# COMPUTE_CLUSTER0_CTL_CFG_PHY register map
Vendor: Texas Instruments
Peripheral module from a debugger description file (folder J7VCL).
Registers are 32-bit, read-write, reset 0x0 unless marked. A register's access mark holds for its fields unless they carry their own. Offsets are as the file gives them; lines under a group give offsets from that group; [hi:lo] are bit positions; {n}, {i} and the like mark numbered series; 'fields as' and 'values as' point back to an identical list; <NAME> marks a mode.

## COMPUTE_CLUSTER0_CTL_CFG_PHY (part 1 of 4)
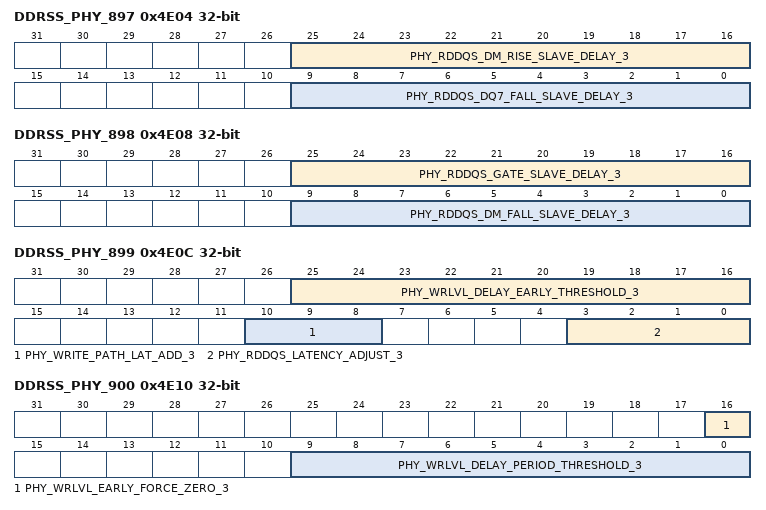
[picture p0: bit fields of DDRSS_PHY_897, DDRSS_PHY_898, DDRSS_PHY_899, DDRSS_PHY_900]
0x4E04 DDRSS_PHY_897
  [25:16] PHY_RDDQS_DM_RISE_SLAVE_DELAY_3 — Rising edge read DQS slave delay setting for DM for slice 3.
  [9:0] PHY_RDDQS_DQ7_FALL_SLAVE_DELAY_3 — Falling edge read DQS slave delay setting for DQ7 for slice 3.
0x4E08 DDRSS_PHY_898
  [25:16] PHY_RDDQS_GATE_SLAVE_DELAY_3 — Read DQS slave delay setting for slice 3.
  [9:0] PHY_RDDQS_DM_FALL_SLAVE_DELAY_3 — Falling edge read DQS slave delay setting for DM for slice 3.
0x4E0C DDRSS_PHY_899
  [25:16] PHY_WRLVL_DELAY_EARLY_THRESHOLD_3 — Write level delay threshold above which will be considered in previous cycle for slice 3.
  [10:8] PHY_WRITE_PATH_LAT_ADD_3 — Number of cycles to delay the incoming dfi_wrdata_en/dfi_wrdata signals for slice 3.
  [3:0] PHY_RDDQS_LATENCY_ADJUST_3 — Number of cycles to delay the incoming dfi_rddata_en for read DQS gate generation for slice 3.
0x4E10 DDRSS_PHY_900
  [16] PHY_WRLVL_EARLY_FORCE_ZERO_3 — Force the final write level delay value (that meets the early threshold) to 0 for slice 3.
  [9:0] PHY_WRLVL_DELAY_PERIOD_THRESHOLD_3 — Write level delay threshold below which will add a cycle of write path latency for slice 3.
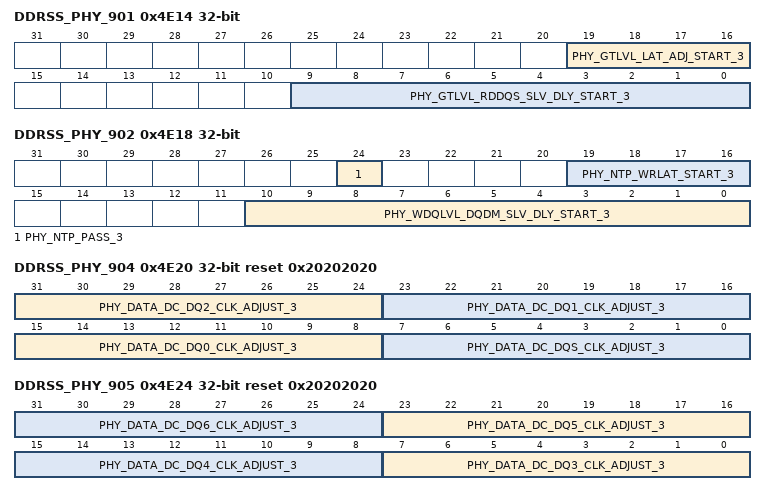
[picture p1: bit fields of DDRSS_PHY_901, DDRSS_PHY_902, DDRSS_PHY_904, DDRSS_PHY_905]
0x4E14 DDRSS_PHY_901
  [19:16] PHY_GTLVL_LAT_ADJ_START_3 — Initial read DQS gate cycle delay from dfi_rddata_en during gate training for slice 3.
  [9:0] PHY_GTLVL_RDDQS_SLV_DLY_START_3 — Initial read DQS gate slave delay setting during gate training for slice 3.
0x4E18 DDRSS_PHY_902
  [24] PHY_NTP_PASS_3 — Indicates if No-topology training found a passing result for slice 3.
  [19:16] PHY_NTP_WRLAT_START_3 — Initial value for phy_write_path_lat_add for No-topology training and early threshold for slice 3.
  [10:0] PHY_WDQLVL_DQDM_SLV_DLY_START_3 — Initial DQ/DM slave delay setting during write data leveling for slice 3.
0x4E1C DDRSS_PHY_903
  [9:0] PHY_RDLVL_RDDQS_DQ_SLV_DLY_START_3 — Read leveling starting value for the DQS/DQ slave delay settings for slice 3.
0x4E20 DDRSS_PHY_904 reset 0x20202020
  [31:24] PHY_DATA_DC_DQ2_CLK_ADJUST_3 — Adjust value of Duty Cycle Adjuster for slice 3.
  [23:16] PHY_DATA_DC_DQ1_CLK_ADJUST_3 — Adjust value of Duty Cycle Adjuster for slice 3.
  [15:8] PHY_DATA_DC_DQ0_CLK_ADJUST_3 — Adjust value of Duty Cycle Adjuster for slice 3.
  [7:0] PHY_DATA_DC_DQS_CLK_ADJUST_3 — Adjust value of Duty Cycle Adjuster for slice 3.
0x4E24 DDRSS_PHY_905 reset 0x20202020
  [8n-17:8n-24] PHY_DATA_DC_DQ{n}_CLK_ADJUST_3 (n=3..6) — Adjust value of Duty Cycle Adjuster for slice 3.
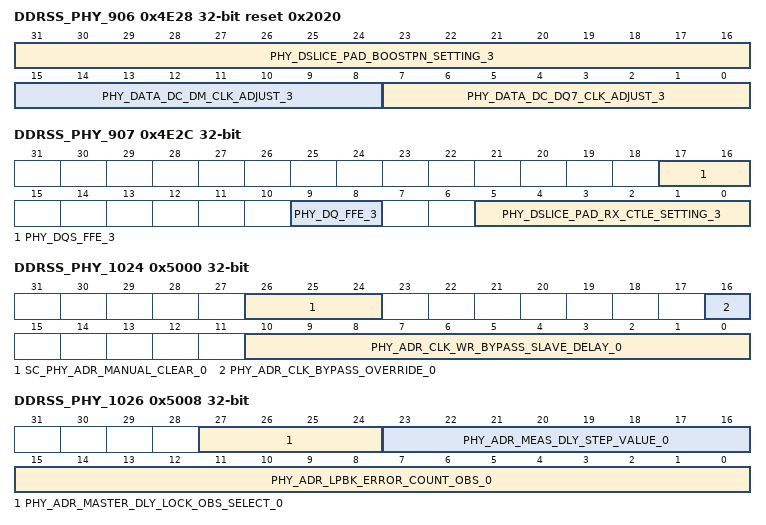
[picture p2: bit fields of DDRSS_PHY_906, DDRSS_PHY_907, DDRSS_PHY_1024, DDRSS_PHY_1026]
0x4E28 DDRSS_PHY_906 reset 0x2020
  [31:16] PHY_DSLICE_PAD_BOOSTPN_SETTING_3 — Setting for boost P/N of pad for slice 3.
  [15:8] PHY_DATA_DC_DM_CLK_ADJUST_3 — Adjust value of Duty Cycle Adjuster for slice 3.
  [7:0] PHY_DATA_DC_DQ7_CLK_ADJUST_3 — Adjust value of Duty Cycle Adjuster for slice 3.
0x4E2C DDRSS_PHY_907
  [17:16] PHY_DQS_FFE_3 — TX_FFE setting for DQS pad for slice 3.
  [9:8] PHY_DQ_FFE_3 — TX_FFE setting for DQ/DM pad for slice 3.
  [5:0] PHY_DSLICE_PAD_RX_CTLE_SETTING_3 — Setting for RX ctle P/N of pad for slice 3.
0x5000 DDRSS_PHY_1024 access per field
  [26:24] SC_PHY_ADR_MANUAL_CLEAR_0 wo — Manual reset/clear of internal logic for address slice 0.
  [16] PHY_ADR_CLK_BYPASS_OVERRIDE_0 rw — Bypass mode override setting for address slice 0.
  [10:0] PHY_ADR_CLK_WR_BYPASS_SLAVE_DELAY_0 rw — Command/Address clock bypass mode slave delay setting for address slice 0.
0x5004 DDRSS_PHY_1025 ro reset 0x1000
  [31:0] PHY_ADR_LPBK_RESULT_OBS_0 — Observation register containing loopback status/results for address slice 0.
0x5008 DDRSS_PHY_1026 access per field
  [27:24] PHY_ADR_MASTER_DLY_LOCK_OBS_SELECT_0 rw — Select value to map the internal master delay observation registers to the accessible master delay observation register for address slice 0.
  [23:16] PHY_ADR_MEAS_DLY_STEP_VALUE_0 ro — Contains the fraction of a cycle in 1 delay element numerator with demominator of 512, for address slice 0.
  [15:0] PHY_ADR_LPBK_ERROR_COUNT_OBS_0 ro — Observation register containing total number of loopback error data for address slice 0.
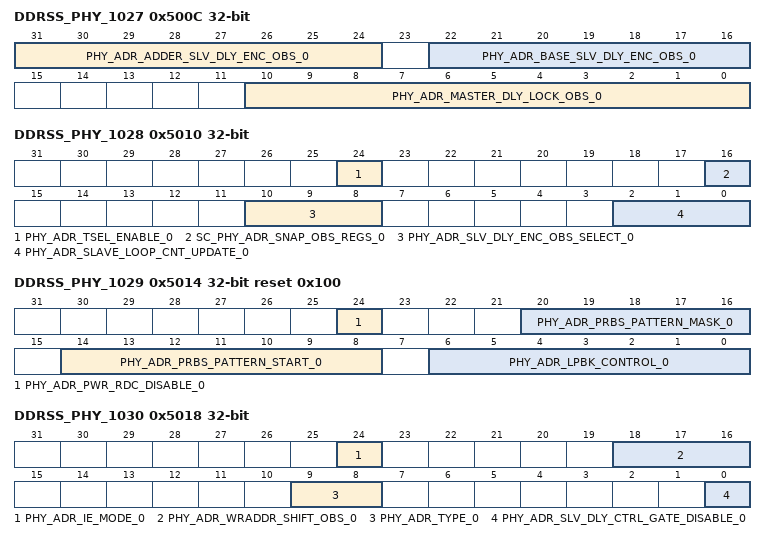
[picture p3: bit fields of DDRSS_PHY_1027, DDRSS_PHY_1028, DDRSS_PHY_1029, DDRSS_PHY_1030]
0x500C DDRSS_PHY_1027 ro
  [31:24] PHY_ADR_ADDER_SLV_DLY_ENC_OBS_0 — Observation register containing addr slave delay for address slice 0.
  [22:16] PHY_ADR_BASE_SLV_DLY_ENC_OBS_0 — Observation register containing base slave delay for address slice 0.
  [10:0] PHY_ADR_MASTER_DLY_LOCK_OBS_0 — Observation register containing master delay results for address slice 0.
0x5010 DDRSS_PHY_1028 access per field
  [24] PHY_ADR_TSEL_ENABLE_0 rw — Enables tsel_en for address slice 0.
  [16] SC_PHY_ADR_SNAP_OBS_REGS_0 wo — Initiates a snapshot of the internal observation registers for address slice 0.
  [10:8] PHY_ADR_SLV_DLY_ENC_OBS_SELECT_0 rw — Select value to map the addr bits delay observation registers to the accessible delay observation register for address slice 0.
  [2:0] PHY_ADR_SLAVE_LOOP_CNT_UPDATE_0 rw — Reserved for address slice 0.
0x5014 DDRSS_PHY_1029 reset 0x100
  [24] PHY_ADR_PWR_RDC_DISABLE_0 — Power reduction disable for address slice 0.
  [20:16] PHY_ADR_PRBS_PATTERN_MASK_0 — PRBS7 mask signal for address slice 0.
  [14:8] PHY_ADR_PRBS_PATTERN_START_0 — PRBS7 start pattern for address slice 0.
  [6:0] PHY_ADR_LPBK_CONTROL_0 — Loopback control bits for address slice 0.
0x5018 DDRSS_PHY_1030 access per field
  [24] PHY_ADR_IE_MODE_0 rw — Input enable control for address slice 0.
  [18:16] PHY_ADR_WRADDR_SHIFT_OBS_0 ro — Observation register containing automatic half cycle and cycle shift values for address slice 0.
  [9:8] PHY_ADR_TYPE_0 rw — DRAM type for address slice 0.
  [0] PHY_ADR_SLV_DLY_CTRL_GATE_DISABLE_0 rw — Power reduction slv_dly_control block gate disable for address slice 0.
0x501C DDRSS_PHY_1031
  [26:0] PHY_ADR_DDL_MODE_0 — DDL mode for address slice 0.
0x5020 DDRSS_PHY_1032
  [5:0] PHY_ADR_DDL_MASK_0 — DDL mask for address slice 0.
0x5024 DDRSS_PHY_1033 ro
  [31:0] PHY_ADR_DDL_TEST_OBS_0 — Observation register containing DDL test bits for address slice 0.
0x5028 DDRSS_PHY_1034 ro
  [31:0] PHY_ADR_DDL_TEST_MSTR_DLY_OBS_0 — Observation register containing master DDL bits for address slice 0.
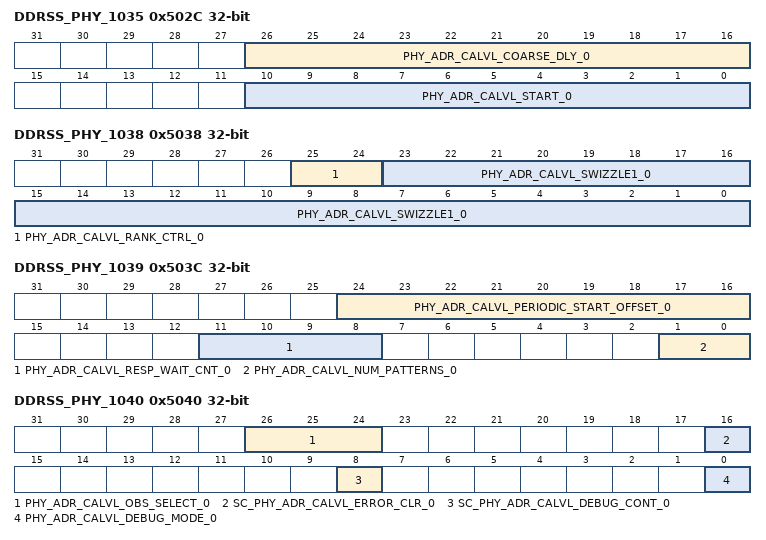
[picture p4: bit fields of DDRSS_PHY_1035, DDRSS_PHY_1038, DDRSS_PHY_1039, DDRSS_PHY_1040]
0x502C DDRSS_PHY_1035
  [26:16] PHY_ADR_CALVL_COARSE_DLY_0 — Coarse CA training DDL increment value for address slice 0.
  [10:0] PHY_ADR_CALVL_START_0 — CA training DDL start value for address slice 0.
0x5030 DDRSS_PHY_1036
  [10:0] PHY_ADR_CALVL_QTR_0 — CA training DDL quarter cycle delay value for address slice 0.
0x5034 DDRSS_PHY_1037
  [23:0] PHY_ADR_CALVL_SWIZZLE0_0 — CA training RD DQ bit swizzle map 0 for address slice 0.
0x5038 DDRSS_PHY_1038
  [25:24] PHY_ADR_CALVL_RANK_CTRL_0 — CA training rank aggregation control bits for address slice 0.
  [23:0] PHY_ADR_CALVL_SWIZZLE1_0 — CA training RD DQ bit swizzle map 1 for address slice 0.
0x503C DDRSS_PHY_1039
  [24:16] PHY_ADR_CALVL_PERIODIC_START_OFFSET_0 — Relative offset to start periodic CALVL from previous result
  [11:8] PHY_ADR_CALVL_RESP_WAIT_CNT_0 — Number of samples to wait before sampling response during CA training for address slice 0.
  [1:0] PHY_ADR_CALVL_NUM_PATTERNS_0 — Number of patterns to use during CA training for address slice 0.
0x5040 DDRSS_PHY_1040 access per field
  [26:24] PHY_ADR_CALVL_OBS_SELECT_0 rw — CA bit lane to observe result from OBS0 during CA training for address slice 0.
  [16] SC_PHY_ADR_CALVL_ERROR_CLR_0 wo — Clears the CA training state machine error status for address slice 0.
  [8] SC_PHY_ADR_CALVL_DEBUG_CONT_0 wo — Allows the CA training state machine to advance (when in debug mode) for address slice 0.
  [0] PHY_ADR_CALVL_DEBUG_MODE_0 rw — Enables CA training debug mode for address slice 0.
0x5044 DDRSS_PHY_1041 ro
  [31:0] PHY_ADR_CALVL_CH0_OBS0_0 — Observation register for CA training for channel 0 slice 0.
0x5048 DDRSS_PHY_1042 ro
  [31:0] PHY_ADR_CALVL_CH1_OBS0_0 — Observation register for CA training for channel 1 slice 0.
0x504C DDRSS_PHY_1043 ro
  [31:0] PHY_ADR_CALVL_OBS1_0 — Observation register contains general CA training bits for slice 0.
0x5050 DDRSS_PHY_1044 ro
  [31:0] PHY_ADR_CALVL_OBS2_0 — Observation register contains periodic CA training bits for slice 0.
0x5054 DDRSS_PHY_1045
  [19:0] PHY_ADR_CALVL_FG_0_0 — CA training foreground pattern 0 for address slice 0.
0x5058 DDRSS_PHY_1046
  [19:0] PHY_ADR_CALVL_BG_0_0 — CA training background pattern 0 for address slice 0.
0x505C DDRSS_PHY_1047
  [19:0] PHY_ADR_CALVL_FG_1_0 — CA training foreground pattern 1 for address slice 0.
0x5060 DDRSS_PHY_1048
  [19:0] PHY_ADR_CALVL_BG_1_0 — CA training background pattern 1 for address slice 0.
0x5064 DDRSS_PHY_1049
  [19:0] PHY_ADR_CALVL_FG_2_0 — CA training foreground pattern 2 for address slice 0.
0x5068 DDRSS_PHY_1050
  [19:0] PHY_ADR_CALVL_BG_2_0 — CA training background pattern 2 for address slice 0.
0x506C DDRSS_PHY_1051
  [19:0] PHY_ADR_CALVL_FG_3_0 — CA training foreground pattern 3 for address slice 0.
0x5070 DDRSS_PHY_1052
  [19:0] PHY_ADR_CALVL_BG_3_0 — CA training background pattern 3 for address slice 0.
0x5074 DDRSS_PHY_1053
  [23:0] PHY_ADR_ADDR_SEL_0 — Selects which DFI address pins connect to which CA pins for LPDDR3/4 for address slice 0.
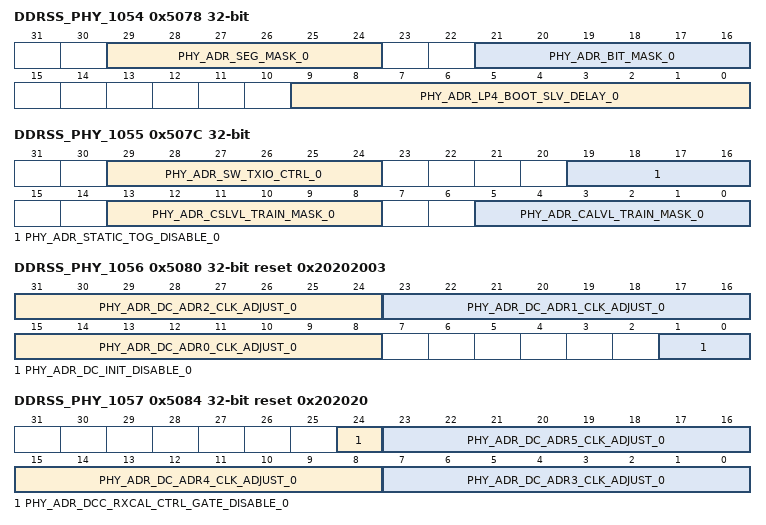
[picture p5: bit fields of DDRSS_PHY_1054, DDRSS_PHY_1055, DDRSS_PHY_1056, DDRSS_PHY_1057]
0x5078 DDRSS_PHY_1054
  [29:24] PHY_ADR_SEG_MASK_0 — Segment mask bit for address slice 0.
  [21:16] PHY_ADR_BIT_MASK_0 — Mask bit for address slice 0.
  [9:0] PHY_ADR_LP4_BOOT_SLV_DELAY_0 — Address slave delay setting during the LPDDR4 boot frequency operation for address slice 0.
0x507C DDRSS_PHY_1055
  [29:24] PHY_ADR_SW_TXIO_CTRL_0 — Controls address pad output enable for address slice 0.
  [19:16] PHY_ADR_STATIC_TOG_DISABLE_0 — Toggle control during static activity for address slice 0.
  [13:8] PHY_ADR_CSLVL_TRAIN_MASK_0 — Mask bit for CS training participation for address slice 0.
  [5:0] PHY_ADR_CALVL_TRAIN_MASK_0 — Mask bit for CA training participation for address slice 0.
0x5080 DDRSS_PHY_1056 reset 0x20202003
  [31:24] PHY_ADR_DC_ADR2_CLK_ADJUST_0 — Adjust value of Clock Duty Cycle Adjuster lane 2 for address slice 0.
  [23:16] PHY_ADR_DC_ADR1_CLK_ADJUST_0 — Adjust value of Clock Duty Cycle Adjuster lane 1 for address slice 0.
  [15:8] PHY_ADR_DC_ADR0_CLK_ADJUST_0 — Adjust value of Clock Duty Cycle Adjuster lane 0 for address slice 0.
  [1:0] PHY_ADR_DC_INIT_DISABLE_0 — Duty Cycle Corrector disable at initialization for address slice 0.
0x5084 DDRSS_PHY_1057 reset 0x202020
  [24] PHY_ADR_DCC_RXCAL_CTRL_GATE_DISABLE_0 — DCC and RX_CAL clk gate disable for address slice 0.
  [23:16] PHY_ADR_DC_ADR5_CLK_ADJUST_0 — Adjust value of Clock Duty Cycle Adjuster lane 5 for address slice 0.
  [15:8] PHY_ADR_DC_ADR4_CLK_ADJUST_0 — Adjust value of Clock Duty Cycle Adjuster lane 4 for address slice 0.
  [7:0] PHY_ADR_DC_ADR3_CLK_ADJUST_0 — Adjust value of Clock Duty Cycle Adjuster lane 3 for address slice 0.
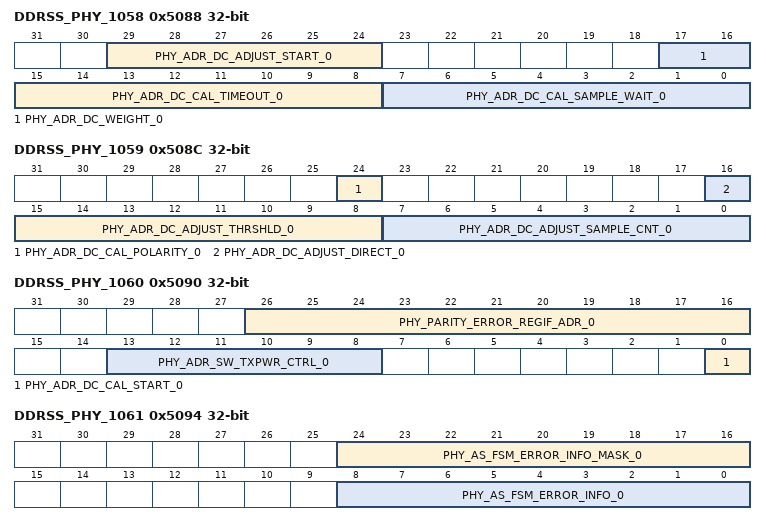
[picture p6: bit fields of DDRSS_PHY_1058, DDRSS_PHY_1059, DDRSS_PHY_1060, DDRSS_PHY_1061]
0x5088 DDRSS_PHY_1058
  [29:24] PHY_ADR_DC_ADJUST_START_0 — DCC calibration starting value for address slice 0.
  [17:16] PHY_ADR_DC_WEIGHT_0 — DCC weighting factor base value for address slice 0.
  [15:8] PHY_ADR_DC_CAL_TIMEOUT_0 — DCC number of iterations to wait before timeout for address slice 0.
  [7:0] PHY_ADR_DC_CAL_SAMPLE_WAIT_0 — DCC cycles to wait after calibration change before sampling results for address slice 0.
0x508C DDRSS_PHY_1059
  [24] PHY_ADR_DC_CAL_POLARITY_0 — DCC calibration polarity for address slice 0.
  [16] PHY_ADR_DC_ADJUST_DIRECT_0 — DCC adjust direction for address slice 0.
  [15:8] PHY_ADR_DC_ADJUST_THRSHLD_0 — DCC adjust threshold around the mid-point for address slice 0.
  [7:0] PHY_ADR_DC_ADJUST_SAMPLE_CNT_0 — DCC number of samples to take for address slice 0.
0x5090 DDRSS_PHY_1060
  [26:16] PHY_PARITY_ERROR_REGIF_ADR_0 — Inject parity error to register interface signals for address slice 0.
  [13:8] PHY_ADR_SW_TXPWR_CTRL_0 — Disable address output enables in deep sleep mode for address slice 0.
  [0] PHY_ADR_DC_CAL_START_0 — DCC Manual trigger for address slice 0.
0x5094 DDRSS_PHY_1061 access per field
  [24:16] PHY_AS_FSM_ERROR_INFO_MASK_0 rw — FSM Error Info Mask for address slice 0.
  [8:0] PHY_AS_FSM_ERROR_INFO_0 ro — FSM Error Info for address slice 0.
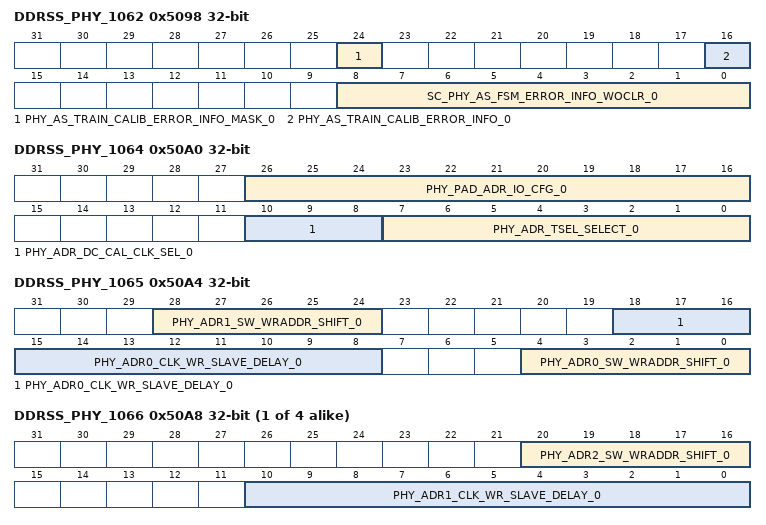
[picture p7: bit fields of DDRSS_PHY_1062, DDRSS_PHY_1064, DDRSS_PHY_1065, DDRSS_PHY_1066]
0x5098 DDRSS_PHY_1062 access per field
  [24] PHY_AS_TRAIN_CALIB_ERROR_INFO_MASK_0 rw — Training/Calibration Error Info Mask for address slice 0.
  [16] PHY_AS_TRAIN_CALIB_ERROR_INFO_0 ro — Training/Calibration Error Info for address slice 0.
  [8:0] SC_PHY_AS_FSM_ERROR_INFO_WOCLR_0 wo — FSM Error Info clear for address slice 0.
0x509C DDRSS_PHY_1063 wo
  [0] SC_PHY_AS_TRAIN_CALIB_ERROR_INFO_WOCLR_0 — Training/Calibration Error Info clear for address slice 0.
0x50A0 DDRSS_PHY_1064
  [26:16] PHY_PAD_ADR_IO_CFG_0 — Controls I/O pads for address pad for address slice 0.
  [10:8] PHY_ADR_DC_CAL_CLK_SEL_0 — DCC CAL clock for address slice 0.
  [7:0] PHY_ADR_TSEL_SELECT_0 — Tsel select values for address slice 0.
0x50A4 DDRSS_PHY_1065
  [28:24] PHY_ADR1_SW_WRADDR_SHIFT_0 — Manual override of CA bit 1 of automatic half_cycle_shift/cycle_shift for address slice 0.
  [18:8] PHY_ADR0_CLK_WR_SLAVE_DELAY_0 — CA bit 0 slave delay setting for address slice 0.
  [4:0] PHY_ADR0_SW_WRADDR_SHIFT_0 — Manual override of CA bit 0 of automatic half_cycle_shift/cycle_shift for address slice 0.
{0x4000+4i} DDRSS_PHY_{i} (i=1066..1069)
  [20:16] PHY_ADR{i-1064}_SW_WRADDR_SHIFT_0 — Manual override of CA bit {i-1064} of automatic half_cycle_shift/cycle_shift for address slice 0.
  [10:0] PHY_ADR{i-1065}_CLK_WR_SLAVE_DELAY_0 — CA bit {i-1065} slave delay setting for address slice 0.
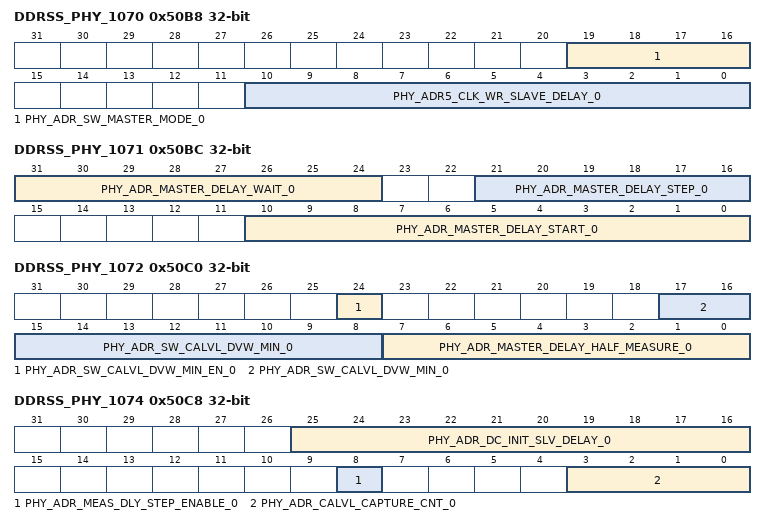
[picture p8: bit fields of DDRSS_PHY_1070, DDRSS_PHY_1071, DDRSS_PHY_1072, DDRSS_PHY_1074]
0x50B8 DDRSS_PHY_1070
  [19:16] PHY_ADR_SW_MASTER_MODE_0 — Master delay line override settings for address slice 0.
  [10:0] PHY_ADR5_CLK_WR_SLAVE_DELAY_0 — CA bit 5 slave delay setting for address slice 0.
0x50BC DDRSS_PHY_1071
  [31:24] PHY_ADR_MASTER_DELAY_WAIT_0 — Wait cycles for master delay line locking algorithm for address slice 0.
  [21:16] PHY_ADR_MASTER_DELAY_STEP_0 — Incremental step size for master delay line locking algorithm for address slice 0.
  [10:0] PHY_ADR_MASTER_DELAY_START_0 — Start value for master delay line locking algorithm for address slice 0.
0x50C0 DDRSS_PHY_1072
  [24] PHY_ADR_SW_CALVL_DVW_MIN_EN_0 — Enables the software override data valid window size during CA training for address slice 0.
  [17:8] PHY_ADR_SW_CALVL_DVW_MIN_0 — Sets the software override data valid window size during CA training for address slice 0.
  [7:0] PHY_ADR_MASTER_DELAY_HALF_MEASURE_0 — Defines the number of delay line elements to be considered in determing whether to lock to a half clock cycle for the master in address slice 0
0x50C4 DDRSS_PHY_1073
  [3:0] PHY_ADR_CALVL_DLY_STEP_0 — Sets the delay step size plus 1 during CA training for address slice 0.
0x50C8 DDRSS_PHY_1074
  [25:16] PHY_ADR_DC_INIT_SLV_DELAY_0 — DCC initialization value of write ADDR slave delay for address slice 0.
  [8] PHY_ADR_MEAS_DLY_STEP_ENABLE_0 — Enables delay parameter setting using phy_adr_meas_dly_step_value for address slice 0.
  [3:0] PHY_ADR_CALVL_CAPTURE_CNT_0 — Number of samples to take at each ADDR slave delay setting during CA training for address slice 0.
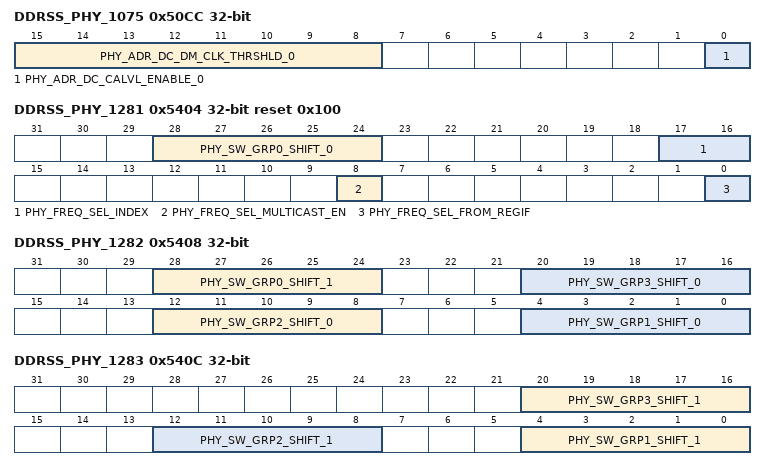
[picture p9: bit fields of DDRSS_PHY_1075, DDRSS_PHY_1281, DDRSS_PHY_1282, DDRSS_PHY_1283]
0x50CC DDRSS_PHY_1075
  [15:8] PHY_ADR_DC_DM_CLK_THRSHLD_0 — DCC clock measurement cell threshold offset for address slice 0.
  [0] PHY_ADR_DC_CALVL_ENABLE_0 — DCC enable duty cycle adjust during CA leveling for address slice 0.
0x5400 DDRSS_PHY_1280
  [1:0] PHY_FREQ_SEL — Specifies which copy of the frequency-dependent timing parameters will be used by the PHY.
0x5404 DDRSS_PHY_1281 reset 0x100
  [28:24] PHY_SW_GRP0_SHIFT_0 — Address slice slave delay setting for address slice 4.
  [17:16] PHY_FREQ_SEL_INDEX — Selects which frequency set to update when PHY_FREQ_SEL_MULTICAST_EN is not set.
  [8] PHY_FREQ_SEL_MULTICAST_EN — When set, a register write will update parameters for all frequency sets simultaneously.
  [0] PHY_FREQ_SEL_FROM_REGIF — Indicates which source is used to select the frequency copy.
0x5408 DDRSS_PHY_1282
  [28:24] PHY_SW_GRP0_SHIFT_1 — Address slice slave delay setting for address slice 4.
  [20:16] PHY_SW_GRP3_SHIFT_0 — Address slice slave delay setting for address slice 4.
  [12:8] PHY_SW_GRP2_SHIFT_0 — Address slice slave delay setting for address slice 4.
  [4:0] PHY_SW_GRP1_SHIFT_0 — Address slice slave delay setting for address slice 4.
0x540C DDRSS_PHY_1283
  [20:16] PHY_SW_GRP3_SHIFT_1 — Address slice slave delay setting for address slice 4.
  [12:8] PHY_SW_GRP2_SHIFT_1 — Address slice slave delay setting for address slice 4.
  [4:0] PHY_SW_GRP1_SHIFT_1 — Address slice slave delay setting for address slice 4.
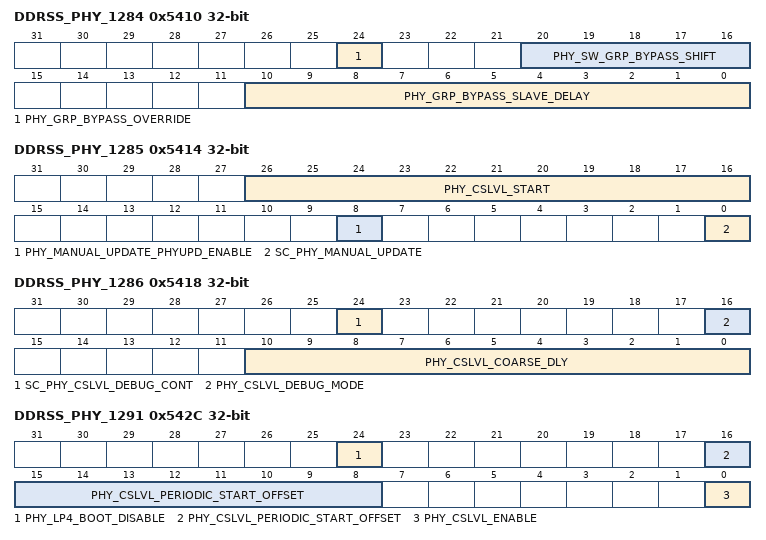
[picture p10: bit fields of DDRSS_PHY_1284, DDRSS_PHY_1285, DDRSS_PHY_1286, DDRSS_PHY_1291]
0x5410 DDRSS_PHY_1284
  [24] PHY_GRP_BYPASS_OVERRIDE — Address/control group slice bypass mode override setting.
  [20:16] PHY_SW_GRP_BYPASS_SHIFT — Address/control group slice bypass mode shift settings.
  [10:0] PHY_GRP_BYPASS_SLAVE_DELAY — Address/control group slice bypass mode slave delay setting.
0x5414 DDRSS_PHY_1285 access per field
  [26:16] PHY_CSLVL_START rw — Defines the CS training DDL start value.
  [8] PHY_MANUAL_UPDATE_PHYUPD_ENABLE rw — Manual update selection of all slave delay line settings.
  [0] SC_PHY_MANUAL_UPDATE wo — Manual update of all slave delay line settings.
0x5418 DDRSS_PHY_1286 access per field
  [24] SC_PHY_CSLVL_DEBUG_CONT wo — Allows the CS training state machine to advance (when in debug mode).
  [16] PHY_CSLVL_DEBUG_MODE rw — Enables CS training debug mode.
  [10:0] PHY_CSLVL_COARSE_DLY rw — Defines the CS training DDL coarse cycle delay value.
0x541C DDRSS_PHY_1287 wo
  [0] SC_PHY_CSLVL_ERROR_CLR — Clears the CS training state machine error status.
0x5420 DDRSS_PHY_1288 ro reset 0x6800000
  [31:0] PHY_CSLVL_OBS0 — Observation register for CS training delay values.
0x5424 DDRSS_PHY_1289 ro
  [31:0] PHY_CSLVL_OBS1 — Observation register for CS training algorithm status.
0x5428 DDRSS_PHY_1290 ro
  [31:0] PHY_CSLVL_OBS2 — Observation register for periodic CS training delay values.
0x542C DDRSS_PHY_1291
  [24] PHY_LP4_BOOT_DISABLE — Controls the handling of the DFI frequency.
  [16:8] PHY_CSLVL_PERIODIC_START_OFFSET — Defines the relative offset from previous LE and TE to start periodic CSLVL with.
  [0] PHY_CSLVL_ENABLE — CS training enable.
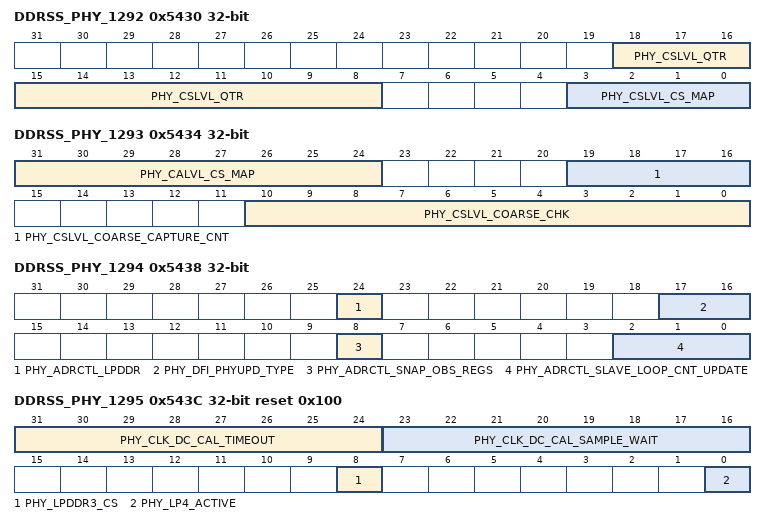
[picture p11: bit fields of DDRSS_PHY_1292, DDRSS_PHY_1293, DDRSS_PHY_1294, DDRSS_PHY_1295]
0x5430 DDRSS_PHY_1292
  [18:8] PHY_CSLVL_QTR — Defines the CS training DDL 1/4 cycle delay value.
  [3:0] PHY_CSLVL_CS_MAP — CS training map.
0x5434 DDRSS_PHY_1293
  [31:24] PHY_CALVL_CS_MAP — Defines the slice numbers associated with each CS during CA training.
  [19:16] PHY_CSLVL_COARSE_CAPTURE_CNT — Defines the number of samples to take at each GRP slave delay setting during CS training coarse CA training.
  [10:0] PHY_CSLVL_COARSE_CHK — Defines the CS training coarse CA training DDL 1/16th cycle delay value.
0x5438 DDRSS_PHY_1294 access per field
  [24] PHY_ADRCTL_LPDDR rw — Adds a cycle of delay for the address/control slices to match the address slice.
  [17:16] PHY_DFI_PHYUPD_TYPE rw — Defines the value of the dfi_phyupd_type output signal to MC.
  [8] PHY_ADRCTL_SNAP_OBS_REGS wo — Initiates a snapshot of the internal observation registers for the address/control block.
  [2:0] PHY_ADRCTL_SLAVE_LOOP_CNT_UPDATE rw — Reserved for the address/control master.
0x543C DDRSS_PHY_1295 reset 0x100
  [31:24] PHY_CLK_DC_CAL_TIMEOUT — Duty cycle correction maximum iteration count.
  [23:16] PHY_CLK_DC_CAL_SAMPLE_WAIT — Number of cal clock cycles to wait for a sample to be taken.
  [8] PHY_LPDDR3_CS — Alters reset state polarity for LPDDR chip selects.
  [0] PHY_LP4_ACTIVE — Indicates an LPDDR4 device is connected to the PHY.
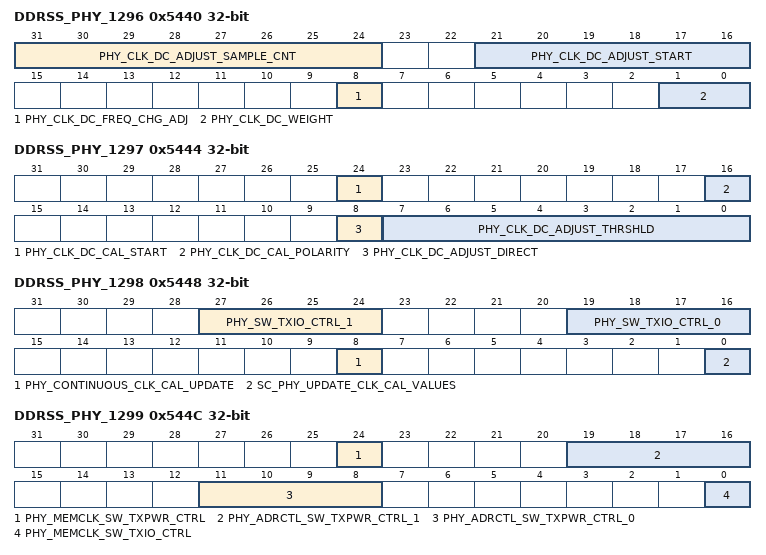
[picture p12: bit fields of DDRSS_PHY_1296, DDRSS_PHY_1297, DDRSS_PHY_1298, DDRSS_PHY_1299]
0x5440 DDRSS_PHY_1296
  [31:24] PHY_CLK_DC_ADJUST_SAMPLE_CNT — Duty cycle correction algorithm sample count per adjustment setting.
  [21:16] PHY_CLK_DC_ADJUST_START — Duty cycle correction algorithm adjustment starting value.
  [8] PHY_CLK_DC_FREQ_CHG_ADJ — Duty cycle correction during frequency change control.
  [1:0] PHY_CLK_DC_WEIGHT — Duty cycle correction weighting factor base value.
0x5444 DDRSS_PHY_1297
  [24] PHY_CLK_DC_CAL_START — Duty cycle correction calibration manual start.
  [16] PHY_CLK_DC_CAL_POLARITY — Duty cycle correction algorithm measurement polarity.
  [8] PHY_CLK_DC_ADJUST_DIRECT — Duty cycle correction algorithm adjustment direction.
  [7:0] PHY_CLK_DC_ADJUST_THRSHLD — Duty cycle correction algorithm threshold delta comparison.
0x5448 DDRSS_PHY_1298 access per field
  [27:24] PHY_SW_TXIO_CTRL_1 rw — This register is used to control if command pad (CS/RAS...) should be shutoff for TX mode.
  [19:16] PHY_SW_TXIO_CTRL_0 rw — This register is used to control if command pad (CS/RAS...) should be shutoff for TX mode.
  [8] PHY_CONTINUOUS_CLK_CAL_UPDATE rw — Continuous update of all latest PVTP,PVTN and PVTR values to the CLK IO pads.
  [0] SC_PHY_UPDATE_CLK_CAL_VALUES wo — Manual update of all latest PVTP,PVTN and PVTR values to the CLK IO pads.
0x544C DDRSS_PHY_1299
  [24] PHY_MEMCLK_SW_TXPWR_CTRL — This register is used to control if clk pads should be shutoff for TX mode in deep sleep mode.
  [19:16] PHY_ADRCTL_SW_TXPWR_CTRL_1 — This register is used to control if address/command pad (address/CS/RAS...) should be shutoff for TX mode in deep sleep mode.
  [11:8] PHY_ADRCTL_SW_TXPWR_CTRL_0 — This register is used to control if address/command pad (address/CS/RAS...) should be shutoff for TX mode in deep sleep mode.
  [0] PHY_MEMCLK_SW_TXIO_CTRL — This register is used to control if clk pads should be shutoff for TX mode.
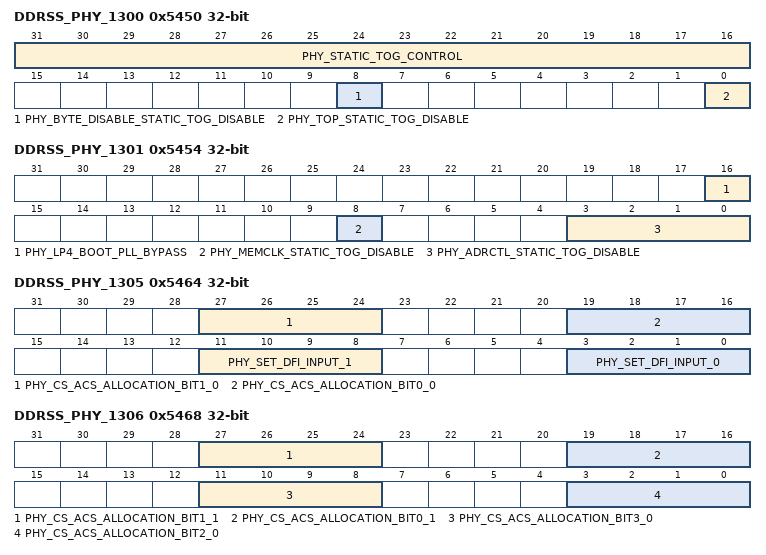
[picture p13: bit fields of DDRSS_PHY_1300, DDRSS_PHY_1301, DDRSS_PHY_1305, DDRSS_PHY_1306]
0x5450 DDRSS_PHY_1300
  [31:16] PHY_STATIC_TOG_CONTROL — Clock divider to create toggle signal.
  [8] PHY_BYTE_DISABLE_STATIC_TOG_DISABLE — Control to disable the toggle signal for data slice during static activity when dfi_data_byte_disable is asserted.
  [0] PHY_TOP_STATIC_TOG_DISABLE — Disables the generation of the toggle for static clock based paths in the PHY to prevent assymetric aging.
0x5454 DDRSS_PHY_1301
  [16] PHY_LP4_BOOT_PLL_BYPASS — PHY clock PLL bypass select.
  [8] PHY_MEMCLK_STATIC_TOG_DISABLE — Control to disable toggle during static activity.
  [3:0] PHY_ADRCTL_STATIC_TOG_DISABLE — Control to disable toggle during static activity.
0x5458 DDRSS_PHY_1302 ro reset 0x10082650
  [31:0] PHY_CLK_SWITCH_OBS — Observation register for Clock switch state machine READ-ONLY
0x545C DDRSS_PHY_1303
  [15:0] PHY_PLL_WAIT — PHY clock PLL wait time after locking.
0x5460 DDRSS_PHY_1304
  [0] PHY_SW_PLL_BYPASS — PHY clock PLL bypass select.
0x5464 DDRSS_PHY_1305
  [27:24] PHY_CS_ACS_ALLOCATION_BIT1_0 — The map for which chip select is associated with each bit in the adrctl slice 0.
  [19:16] PHY_CS_ACS_ALLOCATION_BIT0_0 — The map for which chip select is associated with each bit in the adrctl slice 0.
  [11:8] PHY_SET_DFI_INPUT_1 — Used to indicate the default value of the adrctl slice bits.
  [3:0] PHY_SET_DFI_INPUT_0 — Used to indicate the default value of the adrctl slice bits.
0x5468 DDRSS_PHY_1306
  [27:24] PHY_CS_ACS_ALLOCATION_BIT1_1 — The map for which chip select is associated with each bit in the adrctl slice 1.
  [19:16] PHY_CS_ACS_ALLOCATION_BIT0_1 — The map for which chip select is associated with each bit in the adrctl slice 1.
  [11:8] PHY_CS_ACS_ALLOCATION_BIT3_0 — The map for which chip select is associated with each bit in the adrctl slice 0.
  [3:0] PHY_CS_ACS_ALLOCATION_BIT2_0 — The map for which chip select is associated with each bit in the adrctl slice 0.
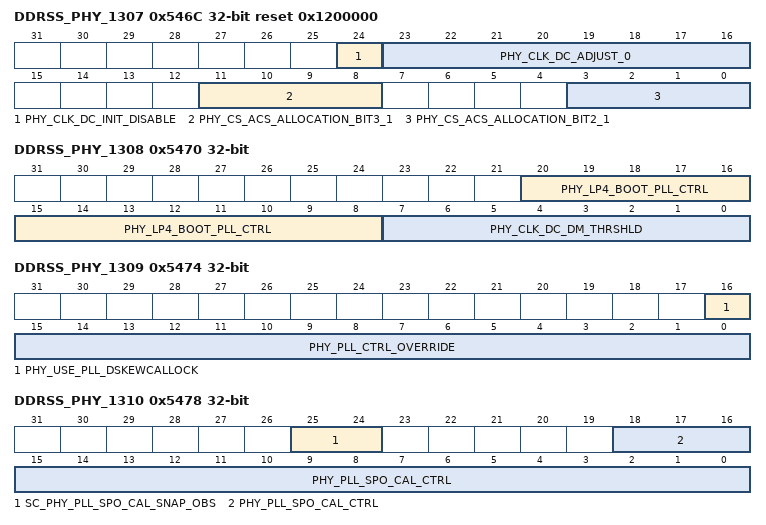
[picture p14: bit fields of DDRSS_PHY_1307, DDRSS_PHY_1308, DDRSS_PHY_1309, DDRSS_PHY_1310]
0x546C DDRSS_PHY_1307 reset 0x1200000
  [24] PHY_CLK_DC_INIT_DISABLE — Disable duty cycle adjust at initialization.
  [23:16] PHY_CLK_DC_ADJUST_0 — Adjust value of Duty Cycle Adjuster for clock slice 0.
  [11:8] PHY_CS_ACS_ALLOCATION_BIT3_1 — The map for which chip select is associated with each bit in the adrctl slice 1.
  [3:0] PHY_CS_ACS_ALLOCATION_BIT2_1 — The map for which chip select is associated with each bit in the adrctl slice 1.
0x5470 DDRSS_PHY_1308
  [20:8] PHY_LP4_BOOT_PLL_CTRL — PHY deskew PLL controls for LPDDR4 boot frequency.
  [7:0] PHY_CLK_DC_DM_THRSHLD — Data measurement cell threshold offset.
0x5474 DDRSS_PHY_1309
  [16] PHY_USE_PLL_DSKEWCALLOCK — Use DSKEWCALLOCK or not.
  [15:0] PHY_PLL_CTRL_OVERRIDE — Individual PHY clock PLL control overrides.
0x5478 DDRSS_PHY_1310 access per field
  [25:24] SC_PHY_PLL_SPO_CAL_SNAP_OBS wo — Register command to take a snapshot of PLL output.
  [18:0] PHY_PLL_SPO_CAL_CTRL rw — PLL SPO Cal controls.
0x547C DDRSS_PHY_1311 access per field
  [17:16] SC_PHY_PLL_CAL_CLK_MEAS wo — Register command to initiate cal_clklout clock frequency measurement.
  [9:0] PHY_PLL_CAL_CLK_MEAS_CYCLES rw — Measurement cycles of cal_clkout clock.
0x5480 DDRSS_PHY_1312 ro
  [15:0] PHY_PLL_OBS_0 — PHY TOP level clock PLL_0 observe values.
0x5484 DDRSS_PHY_1313 ro
  [16:0] PHY_PLL_SPO_CAL_OBS_0 — PHY TOP level PLL_0 SPO Cal observe values.
0x5488 DDRSS_PHY_1314 ro
  [17:0] PHY_PLL_CAL_CLK_MEAS_OBS_0 — PHY TOP level PLL_0 cal_clkout measurement observe values.
0x548C DDRSS_PHY_1315 ro
  [15:0] PHY_PLL_OBS_1 — PHY TOP level clock PLL_1 observe values.
0x5490 DDRSS_PHY_1316 ro
  [16:0] PHY_PLL_SPO_CAL_OBS_1 — PHY TOP level PLL_1 SPO Cal observe values.
0x5494 DDRSS_PHY_1317 access per field
  [24] PHY_LP4_BOOT_LOW_FREQ_SEL rw — Control the PLL domain enter/exit from the negative clock edge for LPDDR4 boot frequency.
  [17:0] PHY_PLL_CAL_CLK_MEAS_OBS_1 ro — PHY TOP level PLL_1 cal_clkout measurement observe values.
0x5498 DDRSS_PHY_1318
  [16] PHY_LS_IDLE_EN — Indicates the Reduced Idle Power State is enabled in low power mode.
  [15:8] PHY_LP_WAKEUP — Specifies the number of cycles the PHY takes to wakeup in low power mode.
  [3:0] PHY_TCKSRE_WAIT — Specifies the number of cycles the PHY should wait before turning off the PLL for a deep sleep or DFS event.
0x549C DDRSS_PHY_1319
  [16] PHY_TDFI_PHY_WRDELAY — DFI timing parameter TDFI_PHY_WRDELAY.
  [9:0] PHY_LP_CTRLUPD_CNTR_CFG — Specifies the number of cycles the PHY takes from light sleep req deassert to ack deassert in low power mode.
0x54A0 DDRSS_PHY_1320 reset 0x4410
  [17:0] PHY_PAD_FDBK_TERM — Controls term settings for gate feedback pads.
0x54A4 DDRSS_PHY_1321 reset 0x4410
  [16:0] PHY_PAD_DATA_TERM — Controls term settings for data pads.
0x54A8 DDRSS_PHY_1322 reset 0x4410
  [16:0] PHY_PAD_DQS_TERM — Controls term settings for dqs pads.
0x54AC DDRSS_PHY_1323 reset 0x4410
  [17:0] PHY_PAD_ADDR_TERM — Controls term settings for the address/control pads.
0x54B0 DDRSS_PHY_1324 reset 0x4410
  [17:0] PHY_PAD_CLK_TERM — Controls term settings for clock pads.
0x54B4 DDRSS_PHY_1325 reset 0x4410
  [17:0] PHY_PAD_CKE_TERM — Controls term settings for cke pads.
0x54B8 DDRSS_PHY_1326 reset 0x4410
  [17:0] PHY_PAD_RST_TERM — Controls term settings for reset_n pads.
0x54BC DDRSS_PHY_1327 reset 0x4410
  [17:0] PHY_PAD_CS_TERM — Controls term settings for cs pads.
0x54C0 DDRSS_PHY_1328 reset 0x4410
  [17:0] PHY_PAD_ODT_TERM — Controls term settings for odt pads.
0x54C4 DDRSS_PHY_1329
  [28:16] PHY_ADRCTL_LP3_RX_CAL — PHY CKE/RESET_N RX calibration controls.
  [9:0] PHY_ADRCTL_RX_CAL — PHY address/control RX calibration controls.
0x54C8 DDRSS_PHY_1330 access per field
  [24] PHY_CAL_START_0 wo — Manual start for the pad calibration state machine for block 0.
  [16] PHY_CAL_CLEAR_0 wo — Clear the pad calibration state machine and results for block 0.
  [12:0] PHY_CAL_MODE_0 rw — Pad calibration mode bits for block 0.
0x54CC DDRSS_PHY_1331
  [31:0] PHY_CAL_INTERVAL_COUNT_0 — Pad calibration interval counter compare value for block 0.
0x54D0 DDRSS_PHY_1332
  [10:8] PHY_LP4_BOOT_CAL_CLK_SELECT_0 — Pad calibration pad clock frequency select setting for LPDDR4 boot frequency for block 0.
  [7:0] PHY_CAL_SAMPLE_WAIT_0 — Pad calibration state machine wait count in pad clock cycles for block 0.
0x54D4 DDRSS_PHY_1333 ro
  [23:0] PHY_CAL_RESULT_OBS_0 — Pad calibration results observation values for block 0.
0x54D8 DDRSS_PHY_1334 ro
  [23:0] PHY_CAL_RESULT2_OBS_0 — Pad calibration results (CKE/RESET_N) observation values for block 0.
0x54DC DDRSS_PHY_1335 ro
  [23:0] PHY_CAL_RESULT4_OBS_0 — Pad calibration pass1 shadow results observation values for block 0.
0x54E0 DDRSS_PHY_1336 ro
  [23:0] PHY_CAL_RESULT5_OBS_0 — Pad calibration pass2 shadow results observation values for block 0.
0x54E4 DDRSS_PHY_1337 ro
  [23:0] PHY_CAL_RESULT6_OBS_0 — Pad calibration internal results observation delta values for block 0.
0x54E8 DDRSS_PHY_1338 access per field
  [30:24] PHY_CAL_CPTR_CNT_0 rw — defines sample capture number in pad calibration process
  [23:0] PHY_CAL_RESULT7_OBS_0 ro — Pad calibration internal results observation delta values for block 0.
0x54EC DDRSS_PHY_1339
  [24] PHY_CAL_DBG_CFG_0 — defines debug configuration in pad calibration process
  [23:16] PHY_CAL_RCV_FINE_ADJ_0 — defines adjustment for RCV code in pad calibration process
  [15:8] PHY_CAL_PD_FINE_ADJ_0 — defines adjustment for PD code in pad calibration process
  [7:0] PHY_CAL_PU_FINE_ADJ_0 — defines adjustment for PU code in pad calibration process
0x54F0 DDRSS_PHY_1340 wo
  [0] SC_PHY_PAD_DBG_CONT_0 — Allows the pad calibration state machine to advance (when in debug mode) for slice 0.
0x54F4 DDRSS_PHY_1341 ro
  [31:0] PHY_CAL_RESULT3_OBS_0 — Pad calibration results first/last0/1 observation values for block 0.
0x54F8 DDRSS_PHY_1342 reset 0x4102000
  [27:8] PHY_CAL_SLOPE_ADJ_0 — defines slope configure in pad calibration process
  [6:0] PHY_ADRCTL_PVT_MAP_0 — defines slope configure in pad calibration process
0x54FC DDRSS_PHY_1343 reset 0x41020
  [19:0] PHY_CAL_SLOPE_ADJ_PASS2_0 — defines slope configure for pass2 in pad calibration process
0x5500 DDRSS_PHY_1344 reset 0xC98C98
  [24:0] PHY_CAL_TWO_PASS_CFG_0 — defines cal_en configure in pad calibration process
0x5504 DDRSS_PHY_1345 reset 0x3F000000
  [29:24] PHY_CAL_RANGE_PASS1_PU_MAX_DELTA_0 — Pad calibration pass1 pu results won't update if out of max delta range .
  [22:0] PHY_CAL_SW_CAL_CFG_0 — defines firmware based pad calibration process
0x5508 DDRSS_PHY_1346 reset 0x3F3F1F3F
  [29:24] PHY_CAL_RANGE_PASS2_PD_MAX_DELTA_0 — Pad calibration pass2 pd results won't update if out of max delta range .
  [21:16] PHY_CAL_RANGE_PASS2_PU_MAX_DELTA_0 — Pad calibration pass2 pu results won't update if out of max delta range .
  [12:8] PHY_CAL_RANGE_PASS1_RX_MAX_DELTA_0 — Pad calibration pass1 rx results won't update if out of max delta range .
  [5:0] PHY_CAL_RANGE_PASS1_PD_MAX_DELTA_0 — Pad calibration pass1 pd results won't update if out of max delta range .
0x550C DDRSS_PHY_1347 reset 0x1F
  [28:24] PHY_CAL_RANGE_PASS1_RX_MIN_DELTA_0 — Pad calibration pass1 rx results won't update if out of min delta range .
  [21:16] PHY_CAL_RANGE_PASS1_PD_MIN_DELTA_0 — Pad calibration pass1 pd results won't update if out of min delta range .
  [13:8] PHY_CAL_RANGE_PASS1_PU_MIN_DELTA_0 — Pad calibration pass1 pu results won't update if out of min delta range .
  [4:0] PHY_CAL_RANGE_PASS2_RX_MAX_DELTA_0 — Pad calibration pass2 rx results won't update if out of max delta range .
0x5510 DDRSS_PHY_1348
  [20:16] PHY_CAL_RANGE_PASS2_RX_MIN_DELTA_0 — Pad calibration pass2 rx results won't update if out of min delta range .
  [13:8] PHY_CAL_RANGE_PASS2_PD_MIN_DELTA_0 — Pad calibration pass2 pd results won't update if out of min delta range .
  [5:0] PHY_CAL_RANGE_PASS2_PU_MIN_DELTA_0 — Pad calibration pass2 pu results won't update if out of min delta range .
0x5514 DDRSS_PHY_1349
  [26:16] PHY_PARITY_ERROR_REGIF_AC — Inject parity error to register interface signals for ac slice.
  [15:0] PHY_PAD_ATB_CTRL — Pad ATB control settings.
0x5518 DDRSS_PHY_1350 access per field
  [25:24] PHY_AC_LPBK_ENABLE rw — Loopback enable for the address/control slices.
  [16] PHY_AC_LPBK_OBS_SELECT rw — Select value to map an individual loopback address/control slice observation register to the global observation register.
  [8] PHY_AC_LPBK_ERR_CLEAR wo — Address/control loopback error clear.
  [0] PHY_ADRCTL_MANUAL_UPDATE wo — Address/control manual update of slave delay lines.
0x551C DDRSS_PHY_1351 reset 0x10000
  [27:24] PHY_AC_PRBS_PATTERN_MASK — PRBS7 mask signal for address/control slice.
  [22:16] PHY_AC_PRBS_PATTERN_START — PRBS7 start pattern for address/control slice.
  [8:0] PHY_AC_LPBK_CONTROL — Address/control slice loopback control setting.
0x5520 DDRSS_PHY_1352 ro
  [31:0] PHY_AC_LPBK_RESULT_OBS — Observation register for the loopback address/control slices.
0x5524 DDRSS_PHY_1353
  [21:16] PHY_AC_CLK_LPBK_CONTROL — Mem clk block loopback control setting.
  [8] PHY_AC_CLK_LPBK_ENABLE — Loopback enable for mem clk blocks.
  [0] PHY_AC_CLK_LPBK_OBS_SELECT — Select value to map an individual loopback mem clk block observation register to the global observation register.
0x5528 DDRSS_PHY_1354 access per field
  [24] PHY_TOP_PWR_RDC_DISABLE rw — top param power reduction disable.
  [16] PHY_AC_PWR_RDC_DISABLE rw — ac slice power reduction disable.
  [15:0] PHY_AC_CLK_LPBK_RESULT_OBS ro — Observation register for loopback mem clk blocks.
0x552C DDRSS_PHY_1355
  [0] PHY_AC_SLV_DLY_CTRL_GATE_DISABLE — ac slice slv_dly_control block power reduction disable.
0x5530 DDRSS_PHY_1356
  [31:0] PHY_DATA_BYTE_ORDER_SEL — Used to define the data slice's byte swap for CA bits 7:0.
0x5534 DDRSS_PHY_1357
  [25:24] PHY_ADRCTL_MSTR_DLY_ENC_SEL_0 — Select adrctl_mstr_dly_enc for the address/control slice 0 .
  [20:16] PHY_CALVL_DEVICE_MAP — Define which device's DQ feedback data bits should be used during CA training
  [8] PHY_LPDDR4_CONNECT — PHY is connected to LPDDR4 devices
  [7:0] PHY_DATA_BYTE_ORDER_SEL_HIGH — Used to define the data slice's byte swap for CA bits
0x5538 DDRSS_PHY_1358
  [1:0] PHY_ADRCTL_MSTR_DLY_ENC_SEL_1 — Select adrctl_mstr_dly_enc for the address/control slice 1 .
0x553C DDRSS_PHY_1359
  [31:0] PHY_DDL_AC_ENABLE — PHY Address/Control DDL BIST mode enable.
0x5540 DDRSS_PHY_1360
  [25:0] PHY_DDL_AC_MODE — PHY Address/Control DDL BIST mode.
0x5544 DDRSS_PHY_1361
  [26:24] PHY_ERR_MASK_EN — PHY ERROR information report mask enable.
  [23:16] PHY_DDL_TRACK_UPD_THRESHOLD_AC — Specify threshold value for PHY init update tracking for AC slice.
  [10:8] PHY_INIT_UPDATE_CONFIG — PHY init update function configuration.
  [5:0] PHY_DDL_AC_MASK — PHY Address/Control DDL BIST mask.
0x5548 DDRSS_PHY_1362
  [2:0] PHY_ERR_STATUS — PHY ERROR information.
{0x4000+4i} DDRSS_PHY_{i} ro (i=1363..1366)
  [31:0] PHY_DS{i-1363}_DQS_ERR_COUNTER — PHY DATA SLICE {i-1363} DQS ERROR counter.
0x555C DDRSS_PHY_1367 access per field reset 0x2
  [27:24] PHY_DS_INIT_COMPLETE_OBS ro — Observation register for dfi_init_complete for data slice.
  [17:8] PHY_AC_INIT_COMPLETE_OBS ro — Observation register for dfi_init_complete for adr and ac slice.
  [1:0] PHY_DLL_RST_EN rw — PHY DDL reset software interface enable.
0x5560 DDRSS_PHY_1368
  [26:24] PHY_GRP_SHIFT_OBS_SELECT — Select value to map an individual address/control group slice automatic cycle/half_cycle shift settings to the observation register.
  [19:16] PHY_GRP_SLV_DLY_ENC_OBS_SELECT — Select value to map an individual address/control group slice slave delay to the encoded value observation register.
  [8] PHY_AC_DCC_RXCAL_CTRL_GATE_DISABLE — Memory clock bit slice DCC block power reduction disable.
  [0] PHY_UPDATE_MASK — Control to disable the generation of dfi_phyupd_req and use of dfi_ctrlupd_req.
0x5564 DDRSS_PHY_1369 ro
  [18:16] PHY_GRP_SHIFT_OBS — Observation register for the address/control group automatic half cycle and cycle shift values.
  [10:0] PHY_GRP_SLV_DLY_ENC_OBS — Observation register for all address/control group slice slave delay encoded values.
0x5568 DDRSS_PHY_1370
  [26:24] PHY_PLL_LOCK_DEASSERT_MASK — PLL Lock de-assert Mask.
  [18:8] PHY_PARITY_ERROR_REGIF_PS — Injects parity error to register interface signals in param_split.
  [0] PHY_PARITY_ERROR_INJECTION_ENABLE — Enable parity error injection.
0x556C DDRSS_PHY_1371 access per field
  [22:16] SC_PHY_PARITY_ERROR_INFO_WOCLR wo — Parity Error Info.
  [14:8] PHY_PARITY_ERROR_INFO_MASK rw — Parity Error Info Mask.
  [6:0] PHY_PARITY_ERROR_INFO ro — Parity Error Info.
0x5570 DDRSS_PHY_1372 access per field
  [29:16] PHY_TIMEOUT_ERROR_INFO_MASK rw — Timeout Error Info Mask.
  [13:0] PHY_TIMEOUT_ERROR_INFO ro — Timeout Error Info.
0x5574 DDRSS_PHY_1373 access per field
  [29:24] PHY_PLL_FREQUENCY_ERROR_MASK rw — PLL Frequency Error Info Mask.
  [19:16] PHY_PLL_FREQUENCY_ERROR ro — PLL Frequency Error Info.
  [13:0] SC_PHY_TIMEOUT_ERROR_INFO_WOCLR wo — Timeout Error Info.
0x5578 DDRSS_PHY_1374 access per field
  [19:8] PHY_PLL_DSKEWCALOUT_MIN rw — PLL DSKEWCALOUT threshold min value.
  [5:0] SC_PHY_PLL_FREQUENCY_ERROR_WOCLR wo — PLL_Frequency Error Info.
0x557C DDRSS_PHY_1375 access per field
  [25:24] PHY_PLL_DSKEWCALOUT_ERROR_INFO_MASK rw — PLL DSKEWCALOUT threshold Error Info Mask.
  [17:16] PHY_PLL_DSKEWCALOUT_ERROR_INFO ro — PLL DSKEWCALOUT threshold Error Info.
  [11:0] PHY_PLL_DSKEWCALOUT_MAX rw — PLL DSKEWCALOUT threshold max value.
0x5580 DDRSS_PHY_1376 access per field
  [16:8] PHY_TOP_FSM_ERROR_INFO ro — Top level FSM Error Info.
  [1:0] SC_PHY_PLL_DSKEWCALOUT_ERROR_INFO_WOCLR wo — PLL DSKEWCALOUT threshold Error Info.
0x5584 DDRSS_PHY_1377 access per field
  [24:16] SC_PHY_TOP_FSM_ERROR_INFO_WOCLR wo — Top level FSM Error Info.
  [8:0] PHY_TOP_FSM_ERROR_INFO_MASK rw — Top level FSM Error Info Mask.
0x5588 DDRSS_PHY_1378 access per field
  [25:16] PHY_FSM_TRANSIENT_ERROR_INFO_MASK rw — Accumulated Top level FSM Error Info Mask.
  [9:0] PHY_FSM_TRANSIENT_ERROR_INFO ro — Accumulated Top level FSM Error Info.
0x558C DDRSS_PHY_1379 access per field
  [25:24] PHY_TOP_TRAIN_CALIB_ERROR_INFO_MASK rw — Training/Calibration Error Info Mask for TOP.
  [17:16] PHY_TOP_TRAIN_CALIB_ERROR_INFO ro — Training/Calibration Error Info for TOP.
  [9:0] SC_PHY_FSM_TRANSIENT_ERROR_INFO_WOCLR wo — Accumulated Top level FSM Error Info.
0x5590 DDRSS_PHY_1380 access per field
  [30:24] SC_PHY_TRAIN_CALIB_ERROR_INFO_WOCLR wo — Training/Calibration Error Info.
  [22:16] PHY_TRAIN_CALIB_ERROR_INFO_MASK rw — Training/Calibration Error Info Mask.
  [14:8] PHY_TRAIN_CALIB_ERROR_INFO ro — Training/Calibration Error Info.
  [1:0] SC_PHY_TOP_TRAIN_CALIB_ERROR_INFO_WOCLR wo — Training/Calibration Error Info for TOP.
0x5594 DDRSS_PHY_1381 access per field
  [13:8] PHY_GLOBAL_ERROR_INFO_MASK rw — Global Error Info Mask.
  [5:0] PHY_GLOBAL_ERROR_INFO ro — Global Error Info.
0x5598 DDRSS_PHY_1382
  [19:0] PHY_TRAINING_TIMEOUT_VALUE — Training timeout value.
0x559C DDRSS_PHY_1383
  [19:0] PHY_INIT_TIMEOUT_VALUE — Init or DFS timeout value.
0x55A0 DDRSS_PHY_1384
  [15:0] PHY_LP_TIMEOUT_VALUE — DFI LP timeout value.
0x55A4 DDRSS_PHY_1385
  [31:0] PHY_PHYUPD_TIMEOUT_VALUE — DFI PHYUPD timeout value.
0x55A8 DDRSS_PHY_1386
  [28:24] PHY_PLL_LOCK_0_MIN_VALUE — PLL min timeout value.
  [19:0] PHY_PHYMSTR_TIMEOUT_VALUE — DFI PHYMSTR timeout value.
0x55AC DDRSS_PHY_1387
  [27:24] PHY_PLL_FREQUENCY_DELTA — Acceptable PLL frequency delta.
  [23:16] PHY_RDDATA_VALID_TIMEOUT_VALUE — RDDATA VALID timeout value.
  [15:0] PHY_PLL_LOCK_TIMEOUT_VALUE — PLL max timeout value.
0x55B0 DDRSS_PHY_1388 access per field
  [29:16] PHY_ADRCTL_FSM_ERROR_INFO_0 ro — ADRCTL slice level FSM Error Info.
  [15:0] PHY_PLL_FREQUENCY_COMPARE_INTERVAL rw — PLL Frequency compare interval.
0x55B4 DDRSS_PHY_1389 access per field
  [29:16] SC_PHY_ADRCTL_FSM_ERROR_INFO_WOCLR_0 wo — ADRCTL Slice level FSM Error Info.
  [13:0] PHY_ADRCTL_FSM_ERROR_INFO_MASK_0 rw — ADRCTL Slice level FSM Error Info Mask.
0x55B8 DDRSS_PHY_1390 access per field
  [29:16] PHY_ADRCTL_FSM_ERROR_INFO_MASK_1 rw — ADRCTL Slice level FSM Error Info Mask.
  [13:0] PHY_ADRCTL_FSM_ERROR_INFO_1 ro — ADRCTL slice level FSM Error Info.
0x55BC DDRSS_PHY_1391 access per field
  [29:16] PHY_MEMCLK_FSM_ERROR_INFO_0 ro — MEMCLK slice level FSM Error Info.
  [13:0] SC_PHY_ADRCTL_FSM_ERROR_INFO_WOCLR_1 wo — ADRCTL Slice level FSM Error Info.
0x55C0 DDRSS_PHY_1392 access per field
  [29:16] SC_PHY_MEMCLK_FSM_ERROR_INFO_WOCLR_0 wo — MEMCLK Slice level FSM Error Info.
  [13:0] PHY_MEMCLK_FSM_ERROR_INFO_MASK_0 rw — MEMCLK Slice level FSM Error Info Mask.
0x55C4 DDRSS_PHY_1393
  [17:0] PHY_PAD_CAL_IO_CFG_0 — Pad calibration Controls PCLK/PARK pin and vref switch.
0x55C8 DDRSS_PHY_1394
  [13:0] PHY_PAD_ACS_IO_CFG — Controls PCLK/PARK pin for acs pad.
0x55CC DDRSS_PHY_1395
  [0] PHY_PLL_BYPASS — PHY clock PLL bypass select.
0x55D0 DDRSS_PHY_1396
  [16] PHY_LOW_FREQ_SEL — Enables the PHY to enter/exit the PLL domain from the negative clock edge.
  [12:0] PHY_PLL_CTRL — PHY clock PLL controls.
0x55D4 DDRSS_PHY_1397
  [27:24] PHY_CSLVL_DLY_STEP — Sets the delay step size plus 1 during CS training.
  [19:16] PHY_CSLVL_CAPTURE_CNT — Defines the number of samples to take at each GRP slave delay setting during CS training.
  [11:0] PHY_PAD_VREF_CTRL_AC — Pad VREF control settings for the address/control.
0x55D8 DDRSS_PHY_1398
  [24] PHY_LVL_MEAS_DLY_STEP_ENABLE — Enables the phy_adr_meas_dly_step_value to be used instead of the phy_cslvl_dly_step parameter.
  [16] PHY_SW_CSLVL_DVW_MIN_EN — Enables the software override data valid window size during CS training.
  [8:0] PHY_SW_CSLVL_DVW_MIN — Sets the software override data valid window size during CS training.
0x55DC DDRSS_PHY_1399
  [26:16] PHY_GRP1_SLAVE_DELAY_0 — Address slice slave delay setting for address slice 1.
  [10:0] PHY_GRP0_SLAVE_DELAY_0 — Address slice slave delay setting for address slice 0.
0x55E0 DDRSS_PHY_1400
  [26:16] PHY_GRP3_SLAVE_DELAY_0 — Address slice slave delay setting for address slice 3.
  [10:0] PHY_GRP2_SLAVE_DELAY_0 — Address slice slave delay setting for address slice 2.
{0x4000+4i} DDRSS_PHY_{i} (i=1401..1404)
  [10:0] PHY_GRP{i-1401}_SLAVE_DELAY_1 — Address slice slave delay setting for address slice {i-1401}.
0x55F4 DDRSS_PHY_1405
  [2:0] PHY_CLK_DC_CAL_CLK_SEL — Determines DCC CAL clock.
0x55F8 DDRSS_PHY_1406 reset 0xFF
  [29:0] PHY_PAD_FDBK_DRIVE — Controls drive settings for gate feedback pads.
0x55FC DDRSS_PHY_1407 reset 0xFF
  [17:0] PHY_PAD_FDBK_DRIVE2 — Controls drive settings (enslice/boost) for gate feedback pads.
0x5600 DDRSS_PHY_1408
  [30:0] PHY_PAD_DATA_DRIVE — Controls drive settings for data pads.
0x5604 DDRSS_PHY_1409
  [31:0] PHY_PAD_DQS_DRIVE — Controls drive settings for dqs pads.
0x5608 DDRSS_PHY_1410 reset 0xFF
  [29:0] PHY_PAD_ADDR_DRIVE — Controls drive settings for the address/control pads.
0x560C DDRSS_PHY_1411 reset 0xFFFF00
  [26:0] PHY_PAD_ADDR_DRIVE2 — Controls drive settings for the address/control pads.
0x5610 DDRSS_PHY_1412 reset 0xFF
  [31:0] PHY_PAD_CLK_DRIVE — Controls drive settings for clock pads.
0x5614 DDRSS_PHY_1413 reset 0xFF
  [17:0] PHY_PAD_CLK_DRIVE2 — Controls drive settings for clock pads.
0x5618 DDRSS_PHY_1414 reset 0xFF
  [29:0] PHY_PAD_CKE_DRIVE — Controls drive settings for cke pads.
0x561C DDRSS_PHY_1415 reset 0x1FFFF00
  [26:0] PHY_PAD_CKE_DRIVE2 — Controls drive settings for cke pads.
0x5620 DDRSS_PHY_1416 reset 0xFF
  [29:0] PHY_PAD_RST_DRIVE — Controls drive settings for reset_n pads.
0x5624 DDRSS_PHY_1417 reset 0x1FFFF00
  [26:0] PHY_PAD_RST_DRIVE2 — Controls drive settings for reset_n pads.
0x5628 DDRSS_PHY_1418 reset 0xFF
  [29:0] PHY_PAD_CS_DRIVE — Controls drive settings for cs pads.
0x562C DDRSS_PHY_1419 reset 0x1FFFF00
  [26:0] PHY_PAD_CS_DRIVE2 — Controls drive settings for cs pads.
0x5630 DDRSS_PHY_1420 reset 0xFF
  [29:0] PHY_PAD_ODT_DRIVE — Controls drive settings for odt pads.
0x5634 DDRSS_PHY_1421 reset 0x1FFFF00
  [26:0] PHY_PAD_ODT_DRIVE2 — Controls drive settings for odt pads.
0x5638 DDRSS_PHY_1422
  [30:24] PHY_CAL_SETTLING_PRD_0 — Number of clock cycles to extend dfi_phyupd_req after the ack is received for settling of final values
  [23:8] PHY_CAL_VREF_SWITCH_TIMER_0 — The settling time for a switch in VREF during IO pad calibration.
  [2:0] PHY_CAL_CLK_SELECT_0 — Pad calibration pad clock frequency select setting for block 0.
